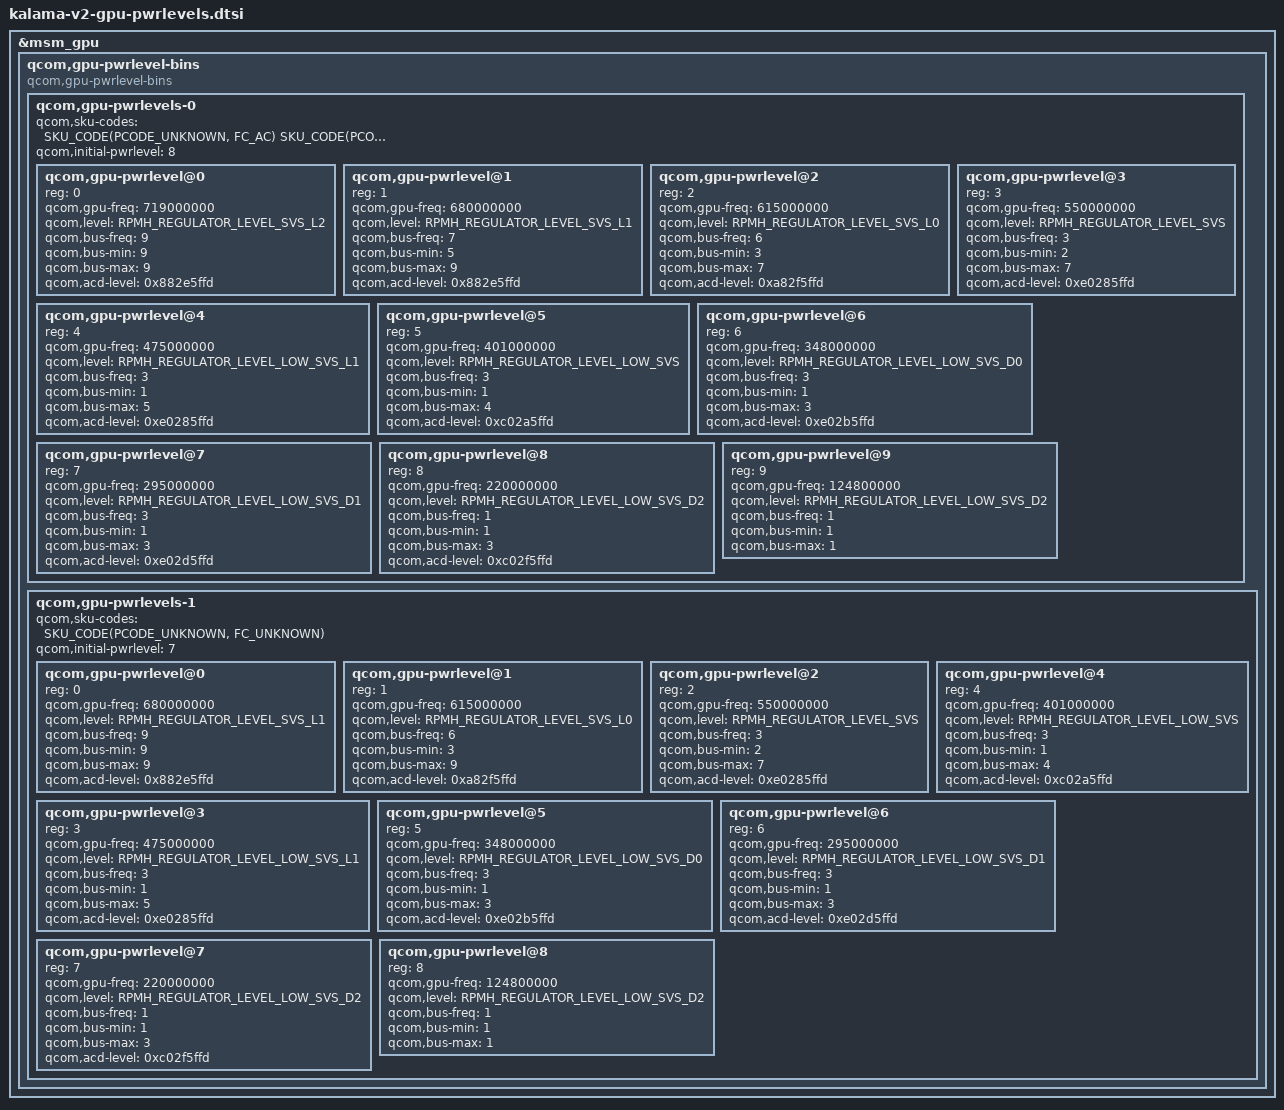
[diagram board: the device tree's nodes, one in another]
&msm_gpu {
	/* Power levels */
	qcom,gpu-pwrlevel-bins {
		compatible="qcom,gpu-pwrlevel-bins";

		#address-cells = <1>;
		#size-cells = <0>;

		qcom,gpu-pwrlevels-0 {

			#address-cells = <1>;
			#size-cells = <0>;

			qcom,sku-codes = <SKU_CODE(PCODE_UNKNOWN, FC_AC)
					SKU_CODE(PCODE_UNKNOWN, FC_AF)
					SKU_CODE(PCODE_2, FC_Y0)
					SKU_CODE(PCODE_2, FC_Y2)
					SKU_CODE(PCODE_4, FC_Y0)
					SKU_CODE(PCODE_4, FC_Y2)
					SKU_CODE(PCODE_6, FC_Y0)
					SKU_CODE(PCODE_6, FC_Y1)
					SKU_CODE(PCODE_6, FC_YD)
					SKU_CODE(PCODE_6, FC_YE)>;

			qcom,initial-pwrlevel = <8>;

			qcom,gpu-pwrlevel@0 {
				reg = <0>;
				qcom,gpu-freq = <719000000>;
				qcom,level = <RPMH_REGULATOR_LEVEL_SVS_L2>;

				qcom,bus-freq = <9>;
				qcom,bus-min = <9>;
				qcom,bus-max = <9>;

				qcom,acd-level = <0x882e5ffd>;
			};
			qcom,gpu-pwrlevel@1 {
				reg = <1>;
				qcom,gpu-freq = <680000000>;
				qcom,level = <RPMH_REGULATOR_LEVEL_SVS_L1>;

				qcom,bus-freq = <7>;
				qcom,bus-min = <5>;
				qcom,bus-max = <9>;

				qcom,acd-level = <0x882e5ffd>;
			};
			qcom,gpu-pwrlevel@2 {
				reg = <2>;
				qcom,gpu-freq = <615000000>;
				qcom,level = <RPMH_REGULATOR_LEVEL_SVS_L0>;

				qcom,bus-freq = <6>;
				qcom,bus-min = <3>;
				qcom,bus-max = <7>;

				qcom,acd-level = <0xa82f5ffd>;
			};
			qcom,gpu-pwrlevel@3 {
				reg = <3>;
				qcom,gpu-freq = <550000000>;
				qcom,level = <RPMH_REGULATOR_LEVEL_SVS>;

				qcom,bus-freq = <3>;
				qcom,bus-min = <2>;
				qcom,bus-max = <7>;

				qcom,acd-level = <0xe0285ffd>;
			};
			qcom,gpu-pwrlevel@4 {
				reg = <4>;
				qcom,gpu-freq = <475000000>;
				qcom,level = <RPMH_REGULATOR_LEVEL_LOW_SVS_L1>;

				qcom,bus-freq = <3>;
				qcom,bus-min = <1>;
				qcom,bus-max = <5>;

				qcom,acd-level = <0xe0285ffd>;
			};
			qcom,gpu-pwrlevel@5 {
				reg = <5>;
				qcom,gpu-freq = <401000000>;
				qcom,level = <RPMH_REGULATOR_LEVEL_LOW_SVS>;

				qcom,bus-freq = <3>;
				qcom,bus-min = <1>;
				qcom,bus-max = <4>;

				qcom,acd-level = <0xc02a5ffd>;
			};
			qcom,gpu-pwrlevel@6 {
				reg = <6>;
				qcom,gpu-freq = <348000000>;
				qcom,level = <RPMH_REGULATOR_LEVEL_LOW_SVS_D0>;

				qcom,bus-freq = <3>;
				qcom,bus-min = <1>;
				qcom,bus-max = <3>;

				qcom,acd-level = <0xe02b5ffd>;
			};
			qcom,gpu-pwrlevel@7 {
				reg = <7>;
				qcom,gpu-freq = <295000000>;
				qcom,level = <RPMH_REGULATOR_LEVEL_LOW_SVS_D1>;

				qcom,bus-freq = <3>;
				qcom,bus-min = <1>;
				qcom,bus-max = <3>;

				qcom,acd-level = <0xe02d5ffd>;
			};
			qcom,gpu-pwrlevel@8 {
				reg = <8>;
				qcom,gpu-freq = <220000000>;
				qcom,level = <RPMH_REGULATOR_LEVEL_LOW_SVS_D2>;

				qcom,bus-freq = <1>;
				qcom,bus-min = <1>;
				qcom,bus-max = <3>;

				qcom,acd-level = <0xc02f5ffd>;
			};
			qcom,gpu-pwrlevel@9 {
				reg = <9>;
				qcom,gpu-freq = <124800000>;
				qcom,level = <RPMH_REGULATOR_LEVEL_LOW_SVS_D2>;

				qcom,bus-freq = <1>;
				qcom,bus-min = <1>;
				qcom,bus-max = <1>;
			};
		};

		qcom,gpu-pwrlevels-1 {

			#address-cells = <1>;
			#size-cells = <0>;

			qcom,sku-codes = <SKU_CODE(PCODE_UNKNOWN, FC_UNKNOWN)>;

			qcom,initial-pwrlevel = <7>;

			qcom,gpu-pwrlevel@0 {
				reg = <0>;
				qcom,gpu-freq = <680000000>;
				qcom,level = <RPMH_REGULATOR_LEVEL_SVS_L1>;

				qcom,bus-freq = <9>;
				qcom,bus-min = <9>;
				qcom,bus-max = <9>;

				qcom,acd-level = <0x882e5ffd>;
			};
			qcom,gpu-pwrlevel@1 {
				reg = <1>;
				qcom,gpu-freq = <615000000>;
				qcom,level = <RPMH_REGULATOR_LEVEL_SVS_L0>;

				qcom,bus-freq = <6>;
				qcom,bus-min = <3>;
				qcom,bus-max = <9>;

				qcom,acd-level = <0xa82f5ffd>;
			};
			qcom,gpu-pwrlevel@2 {
				reg = <2>;
				qcom,gpu-freq = <550000000>;
				qcom,level = <RPMH_REGULATOR_LEVEL_SVS>;

				qcom,bus-freq = <3>;
				qcom,bus-min = <2>;
				qcom,bus-max = <7>;

				qcom,acd-level = <0xe0285ffd>;
			};
			qcom,gpu-pwrlevel@3 {
				reg = <3>;
				qcom,gpu-freq = <475000000>;
				qcom,level = <RPMH_REGULATOR_LEVEL_LOW_SVS_L1>;

				qcom,bus-freq = <3>;
				qcom,bus-min = <1>;
				qcom,bus-max = <5>;

				qcom,acd-level = <0xe0285ffd>;
			};
			qcom,gpu-pwrlevel@4 {
				reg = <4>;
				qcom,gpu-freq = <401000000>;
				qcom,level = <RPMH_REGULATOR_LEVEL_LOW_SVS>;

				qcom,bus-freq = <3>;
				qcom,bus-min = <1>;
				qcom,bus-max = <4>;

				qcom,acd-level = <0xc02a5ffd>;
			};
			qcom,gpu-pwrlevel@5 {
				reg = <5>;
				qcom,gpu-freq = <348000000>;
				qcom,level = <RPMH_REGULATOR_LEVEL_LOW_SVS_D0>;

				qcom,bus-freq = <3>;
				qcom,bus-min = <1>;
				qcom,bus-max = <3>;

				qcom,acd-level = <0xe02b5ffd>;
			};
			qcom,gpu-pwrlevel@6 {
				reg = <6>;
				qcom,gpu-freq = <295000000>;
				qcom,level = <RPMH_REGULATOR_LEVEL_LOW_SVS_D1>;

				qcom,bus-freq = <3>;
				qcom,bus-min = <1>;
				qcom,bus-max = <3>;

				qcom,acd-level = <0xe02d5ffd>;
			};
			qcom,gpu-pwrlevel@7 {
				reg = <7>;
				qcom,gpu-freq = <220000000>;
				qcom,level = <RPMH_REGULATOR_LEVEL_LOW_SVS_D2>;

				qcom,bus-freq = <1>;
				qcom,bus-min = <1>;
				qcom,bus-max = <3>;

				qcom,acd-level = <0xc02f5ffd>;
			};
			qcom,gpu-pwrlevel@8 {
				reg = <8>;
				qcom,gpu-freq = <124800000>;
				qcom,level = <RPMH_REGULATOR_LEVEL_LOW_SVS_D2>;

				qcom,bus-freq = <1>;
				qcom,bus-min = <1>;
				qcom,bus-max = <1>;
			};

		};
	};
};
